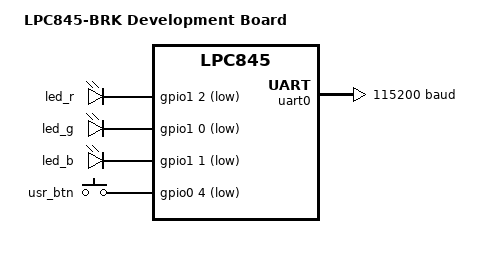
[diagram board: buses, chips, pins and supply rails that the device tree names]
/dts-v1/;

#include <nxp/nxp_lpc845.dtsi>
#include <dt-bindings/gpio/gpio.h>

/ {
    model = "LPC845-BRK Development Board";
    compatible = "nxp,lpc";

    chosen {
        zephyr,sram    = &sram0;
        zephyr,flash   = &flash0;
        zephyr,console = &uart0;
    };

    aliases {
        led0 = &led_r;
        led1 = &led_g;
        led2 = &led_b;
        sw0  = &usr_btn;
    };

    leds {
        compatible = "gpio-leds";
        led_r: led_r { gpios = <&gpio1 2 GPIO_ACTIVE_LOW>; };
        led_g: led_g { gpios = <&gpio1 0 GPIO_ACTIVE_LOW>; };
        led_b: led_b { gpios = <&gpio1 1 GPIO_ACTIVE_LOW>; };
    };

    buttons {
        compatible = "gpio-keys";
        usr_btn: usr_btn { gpios = <&gpio0 4 (GPIO_ACTIVE_LOW | GPIO_PULL_UP)>; };
    };
};

&uart0 {
    pinctrl = <P0_25 P0_24>;
    current-speed = <115200>;
    status = "okay";
};

&gpio0 {
    status = "okay";
};

&gpio1 {
    status = "okay";
};
